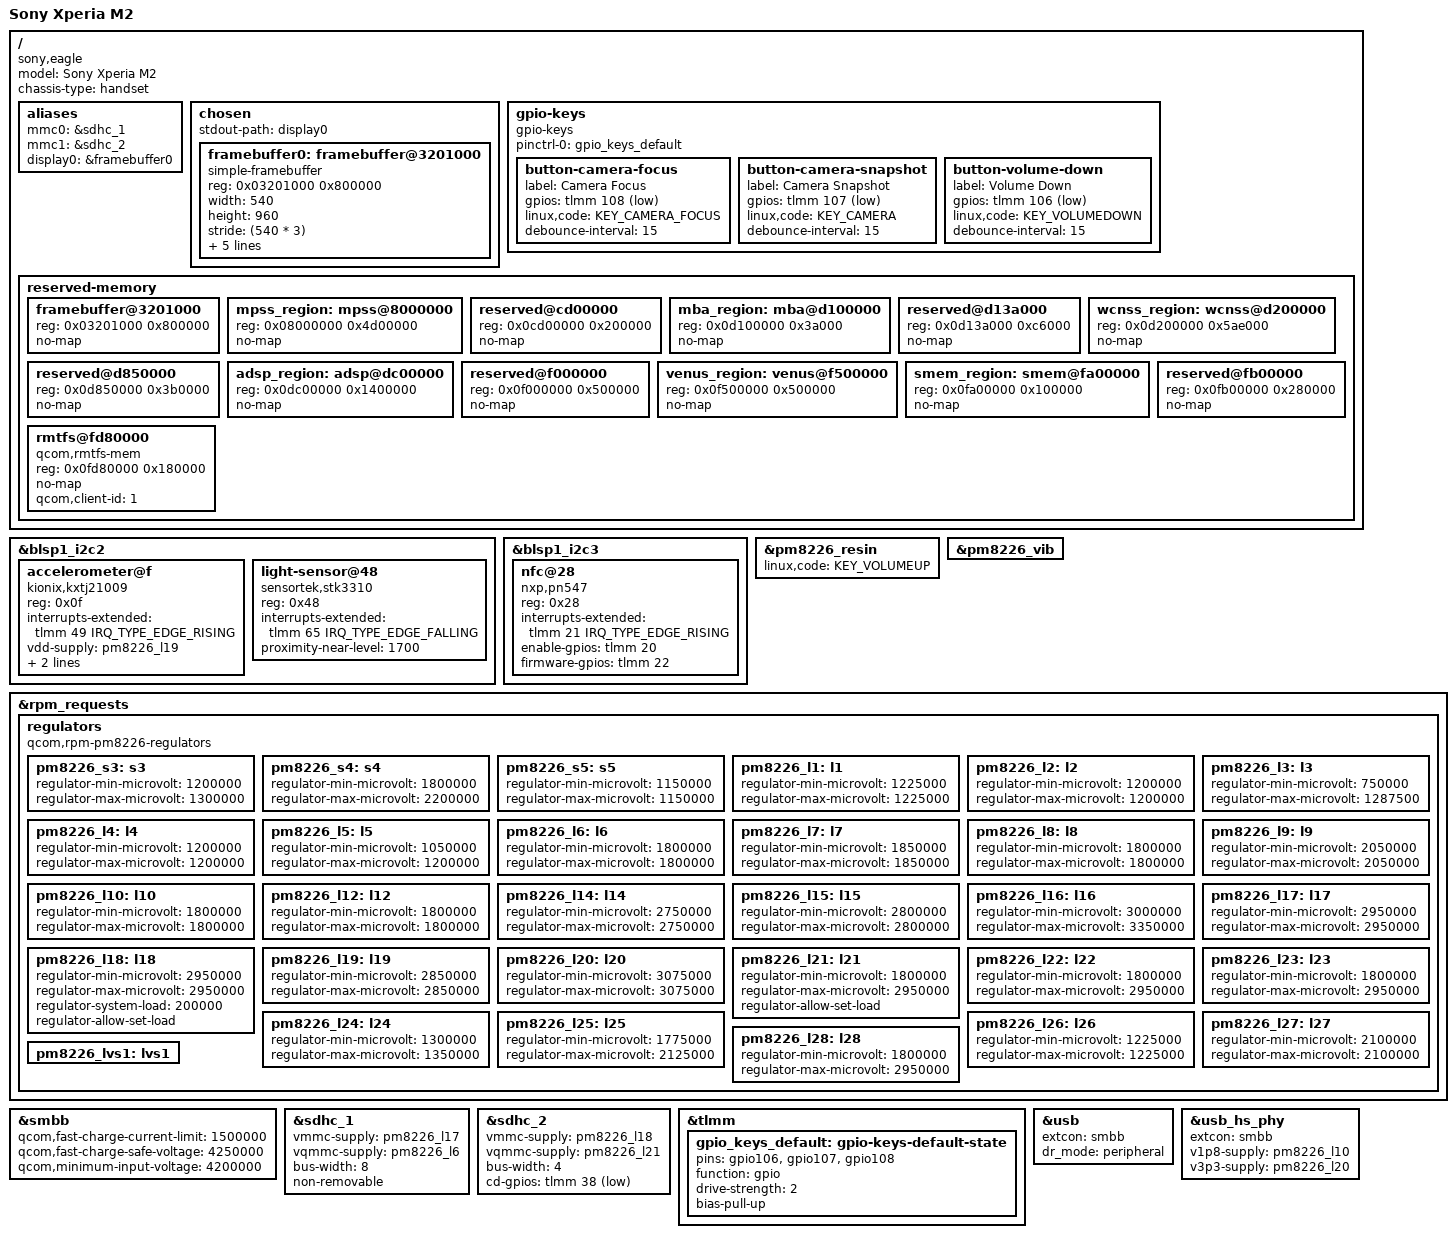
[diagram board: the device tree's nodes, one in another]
// SPDX-License-Identifier: BSD-3-Clause
/*
 * Copyright (c) 2026 Erikas Bitovtas <xerikasxx@gmail.com>
 */

/dts-v1/;

#include "msm8926.dtsi"
#include "pm8226.dtsi"

/delete-node/ &adsp_region;
/delete-node/ &mba_region;
/delete-node/ &mpss_region;
/delete-node/ &smem_region;

/ {
	model = "Sony Xperia M2";
	compatible = "sony,eagle", "qcom,msm8926", "qcom,msm8226";
	chassis-type = "handset";

	aliases {
		mmc0 = &sdhc_1;
		mmc1 = &sdhc_2;
		display0 = &framebuffer0;
	};

	chosen {
		#address-cells = <1>;
		#size-cells = <1>;
		ranges;

		stdout-path = "display0";

		framebuffer0: framebuffer@3201000 {
			compatible = "simple-framebuffer";
			reg = <0x03201000 0x800000>;
			width = <540>;
			height = <960>;
			stride = <(540 * 3)>;
			format = "r8g8b8";

			clocks = <&mmcc MDSS_AHB_CLK>,
				 <&mmcc MDSS_AXI_CLK>,
				 <&mmcc MDSS_BYTE0_CLK>,
				 <&mmcc MDSS_MDP_CLK>,
				 <&mmcc MDSS_PCLK0_CLK>,
				 <&mmcc MDSS_VSYNC_CLK>;
			power-domains = <&mmcc MDSS_GDSC>;
		};
	};

	gpio-keys {
		compatible = "gpio-keys";

		pinctrl-0 = <&gpio_keys_default>;
		pinctrl-names = "default";

		button-camera-focus {
			label = "Camera Focus";
			gpios = <&tlmm 108 GPIO_ACTIVE_LOW>;
			linux,code = <KEY_CAMERA_FOCUS>;
			debounce-interval = <15>;
		};

		button-camera-snapshot {
			label = "Camera Snapshot";
			gpios = <&tlmm 107 GPIO_ACTIVE_LOW>;
			linux,code = <KEY_CAMERA>;
			debounce-interval = <15>;
		};

		button-volume-down {
			label = "Volume Down";
			gpios = <&tlmm 106 GPIO_ACTIVE_LOW>;
			linux,code = <KEY_VOLUMEDOWN>;
			debounce-interval = <15>;
		};
	};

	reserved-memory {
		framebuffer@3201000 {
			reg = <0x03201000 0x800000>;
			no-map;
		};

		mpss_region: mpss@8000000 {
			reg = <0x08000000 0x4d00000>;
			no-map;
		};

		reserved@cd00000 {
			reg = <0x0cd00000 0x200000>;
			no-map;
		};

		mba_region: mba@d100000 {
			reg = <0x0d100000 0x3a000>;
			no-map;
		};

		reserved@d13a000 {
			reg = <0x0d13a000 0xc6000>;
			no-map;
		};

		wcnss_region: wcnss@d200000 {
			reg = <0x0d200000 0x5ae000>;
			no-map;
		};

		reserved@d850000 {
			reg = <0x0d850000 0x3b0000>;
			no-map;
		};

		adsp_region: adsp@dc00000 {
			reg = <0x0dc00000 0x1400000>;
			no-map;
		};

		reserved@f000000 {
			reg = <0x0f000000 0x500000>;
			no-map;
		};

		venus_region: venus@f500000 {
			reg = <0x0f500000 0x500000>;
			no-map;
		};

		smem_region: smem@fa00000 {
			reg = <0x0fa00000 0x100000>;
			no-map;
		};

		reserved@fb00000 {
			reg = <0x0fb00000 0x280000>;
			no-map;
		};

		rmtfs@fd80000 {
			compatible = "qcom,rmtfs-mem";
			reg = <0x0fd80000 0x180000>;
			no-map;

			qcom,client-id = <1>;
		};
	};
};

&blsp1_i2c2 {
	status = "okay";

	accelerometer@f {
		compatible = "kionix,kxtj21009";
		reg = <0x0f>;

		interrupts-extended = <&tlmm 49 IRQ_TYPE_EDGE_RISING>;

		vdd-supply = <&pm8226_l19>;
		vddio-supply = <&pm8226_lvs1>;

		mount-matrix = "0",  "1", "0",
			       "-1", "0", "0",
			       "0",  "0", "1";
	};

	light-sensor@48 {
		compatible = "sensortek,stk3310";
		reg = <0x48>;

		interrupts-extended = <&tlmm 65 IRQ_TYPE_EDGE_FALLING>;

		proximity-near-level = <1700>;
	};
};

&blsp1_i2c3 {
	status = "okay";

	nfc@28 {
		compatible = "nxp,pn547", "nxp,nxp-nci-i2c";
		reg = <0x28>;

		interrupts-extended = <&tlmm 21 IRQ_TYPE_EDGE_RISING>;

		enable-gpios = <&tlmm 20 GPIO_ACTIVE_HIGH>;
		firmware-gpios = <&tlmm 22 GPIO_ACTIVE_HIGH>;
	};
};

&pm8226_resin {
	linux,code = <KEY_VOLUMEUP>;

	status = "okay";
};

&pm8226_vib {
	status = "okay";
};

&rpm_requests {
	regulators {
		compatible = "qcom,rpm-pm8226-regulators";

		pm8226_s3: s3 {
			regulator-min-microvolt = <1200000>;
			regulator-max-microvolt = <1300000>;
		};

		pm8226_s4: s4 {
			regulator-min-microvolt = <1800000>;
			regulator-max-microvolt = <2200000>;
		};

		pm8226_s5: s5 {
			regulator-min-microvolt = <1150000>;
			regulator-max-microvolt = <1150000>;
		};

		pm8226_l1: l1 {
			regulator-min-microvolt = <1225000>;
			regulator-max-microvolt = <1225000>;
		};

		pm8226_l2: l2 {
			regulator-min-microvolt = <1200000>;
			regulator-max-microvolt = <1200000>;
		};

		pm8226_l3: l3 {
			regulator-min-microvolt = <750000>;
			regulator-max-microvolt = <1287500>;
		};

		pm8226_l4: l4 {
			regulator-min-microvolt = <1200000>;
			regulator-max-microvolt = <1200000>;
		};

		pm8226_l5: l5 {
			regulator-min-microvolt = <1050000>;
			regulator-max-microvolt = <1200000>;
		};

		pm8226_l6: l6 {
			regulator-min-microvolt = <1800000>;
			regulator-max-microvolt = <1800000>;
		};

		pm8226_l7: l7 {
			regulator-min-microvolt = <1850000>;
			regulator-max-microvolt = <1850000>;
		};

		pm8226_l8: l8 {
			regulator-min-microvolt = <1800000>;
			regulator-max-microvolt = <1800000>;
		};

		pm8226_l9: l9 {
			regulator-min-microvolt = <2050000>;
			regulator-max-microvolt = <2050000>;
		};

		pm8226_l10: l10 {
			regulator-min-microvolt = <1800000>;
			regulator-max-microvolt = <1800000>;
		};

		pm8226_l12: l12 {
			regulator-min-microvolt = <1800000>;
			regulator-max-microvolt = <1800000>;
		};

		pm8226_l14: l14 {
			regulator-min-microvolt = <2750000>;
			regulator-max-microvolt = <2750000>;
		};

		pm8226_l15: l15 {
			regulator-min-microvolt = <2800000>;
			regulator-max-microvolt = <2800000>;
		};

		pm8226_l16: l16 {
			regulator-min-microvolt = <3000000>;
			regulator-max-microvolt = <3350000>;
		};

		pm8226_l17: l17 {
			regulator-min-microvolt = <2950000>;
			regulator-max-microvolt = <2950000>;
		};

		pm8226_l18: l18 {
			regulator-min-microvolt = <2950000>;
			regulator-max-microvolt = <2950000>;

			regulator-system-load = <200000>;
			regulator-allow-set-load;
		};

		pm8226_l19: l19 {
			regulator-min-microvolt = <2850000>;
			regulator-max-microvolt = <2850000>;
		};

		pm8226_l20: l20 {
			regulator-min-microvolt = <3075000>;
			regulator-max-microvolt = <3075000>;
		};

		pm8226_l21: l21 {
			regulator-min-microvolt = <1800000>;
			regulator-max-microvolt = <2950000>;
			regulator-allow-set-load;
		};

		pm8226_l22: l22 {
			regulator-min-microvolt = <1800000>;
			regulator-max-microvolt = <2950000>;
		};

		pm8226_l23: l23 {
			regulator-min-microvolt = <1800000>;
			regulator-max-microvolt = <2950000>;
		};

		pm8226_l24: l24 {
			regulator-min-microvolt = <1300000>;
			regulator-max-microvolt = <1350000>;
		};

		pm8226_l25: l25 {
			regulator-min-microvolt = <1775000>;
			regulator-max-microvolt = <2125000>;
		};

		pm8226_l26: l26 {
			regulator-min-microvolt = <1225000>;
			regulator-max-microvolt = <1225000>;
		};

		pm8226_l27: l27 {
			regulator-min-microvolt = <2100000>;
			regulator-max-microvolt = <2100000>;
		};

		pm8226_l28: l28 {
			regulator-min-microvolt = <1800000>;
			regulator-max-microvolt = <2950000>;
		};

		pm8226_lvs1: lvs1 {};
	};
};

&smbb {
	qcom,fast-charge-current-limit = <1500000>;
	qcom,fast-charge-safe-voltage = <4250000>;
	qcom,minimum-input-voltage = <4200000>;

	status = "okay";
};

&sdhc_1 {
	vmmc-supply = <&pm8226_l17>;
	vqmmc-supply = <&pm8226_l6>;

	bus-width = <8>;
	non-removable;

	status = "okay";
};

&sdhc_2 {
	vmmc-supply = <&pm8226_l18>;
	vqmmc-supply = <&pm8226_l21>;

	bus-width = <4>;
	cd-gpios = <&tlmm 38 GPIO_ACTIVE_LOW>;

	status = "okay";
};

&tlmm {
	gpio_keys_default: gpio-keys-default-state {
		pins = "gpio106", "gpio107", "gpio108";
		function = "gpio";
		drive-strength = <2>;
		bias-pull-up;
	};
};

&usb {
	extcon = <&smbb>;
	dr_mode = "peripheral";

	status = "okay";
};

&usb_hs_phy {
	extcon = <&smbb>;
	v1p8-supply = <&pm8226_l10>;
	v3p3-supply = <&pm8226_l20>;
};
